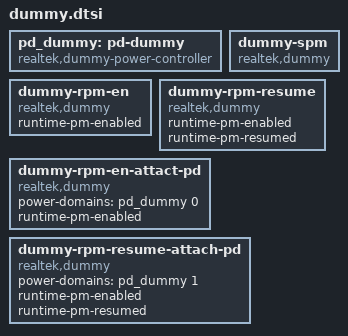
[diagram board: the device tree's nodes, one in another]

pd_dummy: pd-dummy {
	compatible = "realtek,dummy-power-controller";
	#power-domain-cells = <1>;
	status = "okay";
};

dummy-spm {
	compatible = "realtek,dummy";
	status = "okay";
};

dummy-rpm-en {
	compatible = "realtek,dummy";
	runtime-pm-enabled;
	status = "okay";
};

dummy-rpm-resume {
	compatible = "realtek,dummy";
	runtime-pm-enabled;
	runtime-pm-resumed;
	status = "okay";
};

dummy-rpm-en-attact-pd {
	compatible = "realtek,dummy";
	power-domains = <&pd_dummy 0>;
	runtime-pm-enabled;
	status = "okay";
};
dummy-rpm-resume-attach-pd {
	compatible = "realtek,dummy";
	power-domains = <&pd_dummy 1>;
	runtime-pm-enabled;
	runtime-pm-resumed;
	status = "okay";
};
